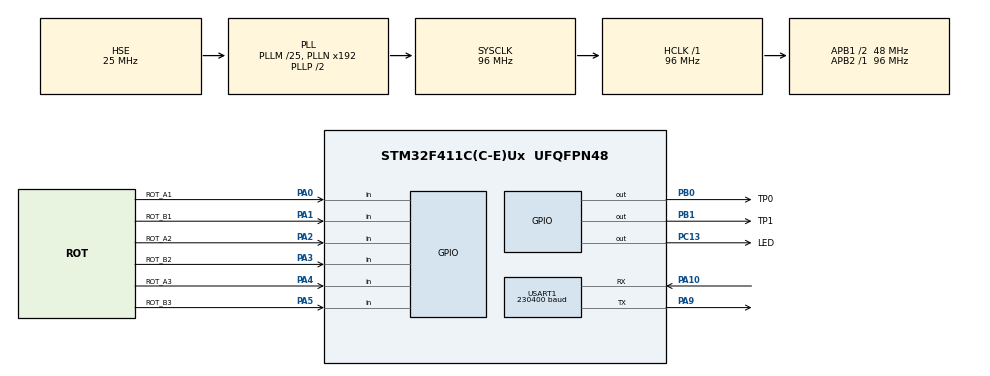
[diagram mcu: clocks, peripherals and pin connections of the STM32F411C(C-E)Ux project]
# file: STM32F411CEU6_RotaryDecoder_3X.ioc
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Dma.Request0=TIM1_UP
Dma.Request1=USART1_TX
Dma.TIM1_UP.0.Direction=DMA_PERIPH_TO_MEMORY
Dma.TIM1_UP.0.FIFOMode=DMA_FIFOMODE_ENABLE
Dma.TIM1_UP.0.FIFOThreshold=DMA_FIFO_THRESHOLD_1QUARTERFULL
Dma.TIM1_UP.0.Instance=DMA2_Stream5
Dma.TIM1_UP.0.MemBurst=DMA_MBURST_INC4
Dma.TIM1_UP.0.MemDataAlignment=DMA_MDATAALIGN_BYTE
Dma.TIM1_UP.0.MemInc=DMA_MINC_ENABLE
Dma.TIM1_UP.0.Mode=DMA_CIRCULAR
Dma.TIM1_UP.0.PeriphBurst=DMA_PBURST_SINGLE
Dma.TIM1_UP.0.PeriphDataAlignment=DMA_PDATAALIGN_BYTE
Dma.TIM1_UP.0.PeriphInc=DMA_PINC_DISABLE
Dma.TIM1_UP.0.Priority=DMA_PRIORITY_VERY_HIGH
Dma.USART1_TX.1.Direction=DMA_MEMORY_TO_PERIPH
Dma.USART1_TX.1.FIFOMode=DMA_FIFOMODE_DISABLE
Dma.USART1_TX.1.Instance=DMA2_Stream7
Dma.USART1_TX.1.MemDataAlignment=DMA_MDATAALIGN_BYTE
Dma.USART1_TX.1.MemInc=DMA_MINC_ENABLE
Dma.USART1_TX.1.Mode=DMA_NORMAL
Dma.USART1_TX.1.PeriphDataAlignment=DMA_PDATAALIGN_BYTE
Dma.USART1_TX.1.PeriphInc=DMA_PINC_DISABLE
Dma.USART1_TX.1.Priority=DMA_PRIORITY_LOW
Mcu.Family=STM32F4
Mcu.Name=STM32F411C(C-E)Ux
Mcu.Package=UFQFPN48
NVIC.DMA2_Stream5_IRQn=true\:0\:0\:false\:false\:true\:false\:true\:true
NVIC.DMA2_Stream7_IRQn=true\:0\:0\:false\:false\:true\:false\:true\:true
NVIC.PriorityGroup=NVIC_PRIORITYGROUP_4
NVIC.RCC_IRQn=true\:0\:0\:false\:false\:true\:true\:false\:true
NVIC.TIM2_IRQn=true\:0\:0\:false\:false\:true\:true\:true\:true
NVIC.USART1_IRQn=true\:0\:0\:false\:false\:true\:true\:true\:true
PA0-WKUP.GPIO_Label=ROT_A1
PA0-WKUP.GPIO_PuPd=GPIO_NOPULL
PA0-WKUP.Signal=GPIO_Input
PA1.GPIO_Label=ROT_B1
PA1.GPIO_PuPd=GPIO_NOPULL
PA1.Signal=GPIO_Input
PA10.Mode=Asynchronous
PA10.Signal=USART1_RX
PA13.Mode=Serial_Wire
PA13.Signal=SYS_JTMS-SWDIO
PA14.Mode=Serial_Wire
PA14.Signal=SYS_JTCK-SWCLK
PA2.GPIO_Label=ROT_A2
PA2.GPIO_PuPd=GPIO_NOPULL
PA2.Signal=GPIO_Input
PA3.GPIO_Label=ROT_B2
PA3.GPIO_PuPd=GPIO_NOPULL
PA3.Signal=GPIO_Input
PA4.GPIO_Label=ROT_A3
PA4.GPIO_PuPd=GPIO_NOPULL
PA4.Signal=GPIO_Input
PA5.GPIO_Label=ROT_B3
PA5.GPIO_PuPd=GPIO_NOPULL
PA5.Signal=GPIO_Input
PA9.Mode=Asynchronous
PA9.Signal=USART1_TX
PB0.GPIO_Label=TP0
PB0.GPIO_Speed=GPIO_SPEED_FREQ_VERY_HIGH
PB0.Signal=GPIO_Output
PB1.GPIO_Label=TP1
PB1.GPIO_Speed=GPIO_SPEED_FREQ_VERY_HIGH
PB1.Signal=GPIO_Output
PC13-ANTI_TAMP.GPIO_Label=LED
PC13-ANTI_TAMP.GPIO_ModeDefaultOutputPP=GPIO_MODE_OUTPUT_OD
PC13-ANTI_TAMP.Signal=GPIO_Output
PC14-OSC32_IN.Mode=LSE-External-Oscillator
PC14-OSC32_IN.Signal=RCC_OSC32_IN
PC15-OSC32_OUT.Mode=LSE-External-Oscillator
PC15-OSC32_OUT.Signal=RCC_OSC32_OUT
PH0\ -\ OSC_IN.Mode=HSE-External-Oscillator
PH0\ -\ OSC_IN.Signal=RCC_OSC_IN
PH1\ -\ OSC_OUT.Mode=HSE-External-Oscillator
PH1\ -\ OSC_OUT.Signal=RCC_OSC_OUT
ProjectManager.HeapSize=0x200
ProjectManager.StackSize=0x400
ProjectManager.TargetToolchain=STM32CubeIDE
RCC.48MHZClocksFreq_Value=48000000
RCC.AHBFreq_Value=96000000
RCC.APB1CLKDivider=RCC_HCLK_DIV2
RCC.APB1Freq_Value=48000000
RCC.APB1TimFreq_Value=96000000
RCC.APB2Freq_Value=96000000
RCC.APB2TimFreq_Value=96000000
RCC.CortexFreq_Value=96000000
RCC.HCLKFreq_Value=96000000
RCC.HSE_VALUE=25000000
RCC.HSI_VALUE=16000000
RCC.PLLM=25
RCC.PLLSourceVirtual=RCC_PLLSOURCE_HSE
RCC.SYSCLKFreq_VALUE=96000000
RCC.SYSCLKSource=RCC_SYSCLKSOURCE_PLLCLK
RCC.VCOOutputFreq_Value=192000000
TIM1.Period=TIM1_COUNTER
TIM1.Prescaler=TIM1_PRESCALER
TIM2.Period=9999
TIM2.Prescaler=95
USART1.BaudRate=230400
USART1.VirtualMode=VM_ASYNC
VP_TIM1_VS_ClockSourceINT.Mode=Internal
VP_TIM2_VS_ClockSourceINT.Mode=Internal
board=custom

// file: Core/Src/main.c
/* USER CODE BEGIN Header */
/**
  ******************************************************************************
  * @file           : main.c
  * @brief          : Main program body
  ******************************************************************************
  * @attention
  *
  * Copyright (c) 2025 STMicroelectronics.
  * All rights reserved.
  *
  * This software is licensed under terms that can be found in the LICENSE file
  * in the root directory of this software component.
  * If no LICENSE file comes with this software, it is provided AS-IS.
  *
  ******************************************************************************
  */
/* USER CODE END Header */
#include "main.h"
#include "dma.h"
#include "tim.h"
#include "usart.h"
#include "gpio.h"

/* USER CODE BEGIN Includes */
#include "app.h"
/* USER CODE END Includes */

void SystemClock_Config(void);

int main(void)
{

  /* MCU Configuration--------------------------------------------------------*/

  /* Reset of all peripherals, Initializes the Flash interface and the Systick. */
  HAL_Init();

  /* Configure the system clock */
  SystemClock_Config();

  /* Initialize all configured peripherals */
  MX_GPIO_Init();
  MX_DMA_Init();
  MX_TIM1_Init();
  MX_USART1_UART_Init();
  MX_TIM2_Init();
  /* USER CODE BEGIN 2 */
  app_begin();
  /* USER CODE END 2 */

  /* Infinite loop */
  /* USER CODE BEGIN WHILE */
  while (1)
  {
	app_loop();
    /* USER CODE END WHILE */

  }
}

void SystemClock_Config(void)
{
  RCC_OscInitTypeDef RCC_OscInitStruct = {0};
  RCC_ClkInitTypeDef RCC_ClkInitStruct = {0};

  /** Configure the main internal regulator output voltage
  */
  __HAL_RCC_PWR_CLK_ENABLE();
  __HAL_PWR_VOLTAGESCALING_CONFIG(PWR_REGULATOR_VOLTAGE_SCALE1);

  /** Initializes the RCC Oscillators according to the specified parameters
  * in the RCC_OscInitTypeDef structure.
  */
  RCC_OscInitStruct.OscillatorType = RCC_OSCILLATORTYPE_HSE;
  RCC_OscInitStruct.HSEState = RCC_HSE_ON;
  RCC_OscInitStruct.PLL.PLLState = RCC_PLL_ON;
  RCC_OscInitStruct.PLL.PLLSource = RCC_PLLSOURCE_HSE;
  RCC_OscInitStruct.PLL.PLLM = 25;
  RCC_OscInitStruct.PLL.PLLN = 192;
  RCC_OscInitStruct.PLL.PLLP = RCC_PLLP_DIV2;
  RCC_OscInitStruct.PLL.PLLQ = 4;
  if (HAL_RCC_OscConfig(&RCC_OscInitStruct) != HAL_OK)
  {
    Error_Handler();
  }

  /** Initializes the CPU, AHB and APB buses clocks
  */
  RCC_ClkInitStruct.ClockType = RCC_CLOCKTYPE_HCLK|RCC_CLOCKTYPE_SYSCLK
                              |RCC_CLOCKTYPE_PCLK1|RCC_CLOCKTYPE_PCLK2;
  RCC_ClkInitStruct.SYSCLKSource = RCC_SYSCLKSOURCE_PLLCLK;
  RCC_ClkInitStruct.AHBCLKDivider = RCC_SYSCLK_DIV1;
  RCC_ClkInitStruct.APB1CLKDivider = RCC_HCLK_DIV2;
  RCC_ClkInitStruct.APB2CLKDivider = RCC_HCLK_DIV1;

  if (HAL_RCC_ClockConfig(&RCC_ClkInitStruct, FLASH_LATENCY_3) != HAL_OK)
  {
    Error_Handler();
  }
}

void Error_Handler(void)
{
  __disable_irq();
  while (1)
  {
  }
}
